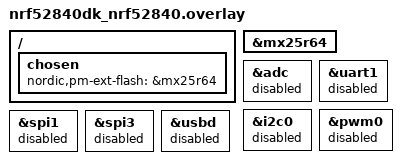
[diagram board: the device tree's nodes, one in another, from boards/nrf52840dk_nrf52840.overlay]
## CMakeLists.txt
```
#
# Nuki-to-Matter-over-Thread gateway.
# Based on the nRF Connect SDK Matter Bridge application
# (Copyright (c) 2023 Nordic Semiconductor ASA, LicenseRef-Nordic-5-Clause).
#

cmake_minimum_required(VERSION 3.20.0)

find_package(Zephyr HINTS $ENV{ZEPHYR_BASE})

project(nuki-matter-gateway)

# Bridge core, Matter identity, network log: firmware/common
include(${CMAKE_CURRENT_SOURCE_DIR}/../common/common.cmake)

target_include_directories(app PRIVATE
  src
  src/matter
  src/nuki
)

target_sources(app PRIVATE
  src/app_task.cpp
  src/main.cpp
  src/gateway_shell.cpp
  src/matter/door_lock_device.cpp
  src/matter/nuki_matter.cpp
  src/nuki/nuki_proto.c
  src/nuki/nuki_port.c
  src/nuki/nuki_client.cpp
  src/nuki/tweetnacl/tweetnacl.c
)
target_sources_ifdef(CONFIG_SHELL app PRIVATE src/nuki/nuki_shell.cpp)

# Status page (firmware/common/web): src/web/index.html and its JSON
target_sources_ifdef(CONFIG_GATEWAY_WEB app PRIVATE src/web_status.cpp)

# TweetNaCl as published (public domain, tweetnacl.cr.yp.to 20140427): no warnings for code we don't change
set_source_files_properties(src/nuki/tweetnacl/tweetnacl.c PROPERTIES COMPILE_OPTIONS "-w")

ncs_configure_data_model()
```

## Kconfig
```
#
# Nuki-to-Matter-over-Thread gateway.
# Based on the nRF Connect SDK Matter Bridge application
# (Copyright (c) 2023 Nordic Semiconductor, LicenseRef-Nordic-5-Clause).
#
mainmenu "Nuki-to-Matter-over-Thread Gateway"

# Bluetooth LE central for the lock, next to Matter's commissioning peripheral
config BT_CENTRAL
	default y

config BT_GATT_CLIENT
	default y

config BT_GATT_DM
	default y

# The Nuki thread waits on k_event bits set by the Bluetooth callbacks.
config EVENTS
	default y

menu "Nuki gateway"

config GATEWAY_NUKI_NAME
	string "Name of the gateway in the Nuki app"
	default "Thread Gateway"
	help
	  Sent to the lock when pairing; at most 32 bytes.

config GATEWAY_NUKI_APP_ID
	int "ID the gateway presents to the lock"
	default 2020003
	help
	  Sent when pairing and with every lock action (the lock's activity
	  log). The ESP32 bridge (nuki_matter) uses 2020002.

choice GATEWAY_NUKI_ID_TYPE
	prompt "Authorization type"
	default GATEWAY_NUKI_ID_TYPE_APP

config GATEWAY_NUKI_ID_TYPE_APP
	bool "App"
	help
	  The gateway pairs like a phone with the Nuki app. A lock accepts
	  several app authorizations, so this works next to a bridge (nuki_hub,
	  the ESP32 bridge or the Nuki Bridge).

config GATEWAY_NUKI_ID_TYPE_BRIDGE
	bool "Bridge"
	help
	  The gateway pairs as a bridge, like the Nuki Bridge, nuki_hub and the
	  ESP32 bridge.

endchoice

config GATEWAY_NUKI_LOCK_LABEL
	string "Matter name of the lock (endpoint 4)"
	default "Front door"
	help
	  Lock and Unlock move the bolt only.

config GATEWAY_NUKI_OPENER_LABEL
	string "Matter name of the door opener (endpoint 3)"
	default "Door opener"
	help
	  Unlock pulls the latch (opens the door); it then shows Locked again.

config GATEWAY_NUKI_POLL_INTERVAL_S
	int "Read the lock state at least this often (s)"
	default 600
	help
	  The lock's beacon flags new state, which is then read at once; the poll
	  only covers missed beacons.

config GATEWAY_NUKI_PAIRING_SEARCH_S
	int "Look for a lock in pairing mode this long after `nuki pair` (s)"
	default 60

config GATEWAY_NUKI_ACTION_ATTEMPTS
	int "Attempts per lock action"
	default 3
	help
	  A failed connection, a missing reply or a busy lock is retried.

config GATEWAY_NUKI_SCAN_INTERVAL
	int "Beacon scan interval (x0.625 ms)"
	default 160
	help
	  Passive scan for the lock's beacon while idle. Default: 160 (100 ms).

config GATEWAY_NUKI_SCAN_WINDOW
	int "Beacon scan window (x0.625 ms)"
	default 40
	help
	  Listening time per interval. Keep it well below the interval so Thread
	  keeps enough radio time. Default: 40 (25 ms, 25 % duty cycle).

config GATEWAY_NUKI_STACK_SIZE
	int "Stack size of the Nuki thread"
	default 5120
	help
	  TweetNaCl's Curve25519 (pairing only) needs about 2 KB.

module = GATEWAY_NUKI
module-str = Gateway Nuki
source "subsys/logging/Kconfig.template.log_config"

endmenu

rsource "../common/Kconfig"
```

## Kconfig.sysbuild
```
#
# Nuki-to-Matter-over-Thread gateway (nRF52840, single core).
# Based on the nRF Connect SDK Matter Bridge application
# (Copyright (c) 2023 Nordic Semiconductor, LicenseRef-Nordic-5-Clause).
#

# The Pro Micro has no external flash, so there is no room for a second image slot:
# it runs without MCUboot and the app uses the whole internal flash.
choice BOOTLOADER
	default BOOTLOADER_NONE if "$(BOARD)" = "promicro_nrf52840"
	default BOOTLOADER_MCUBOOT
endchoice

# Matter OTA needs MCUboot and the second slot.
config MATTER_OTA
	default n if "$(BOARD)" = "promicro_nrf52840"

if BOOTLOADER_MCUBOOT

config DFU_MULTI_IMAGE_PACKAGE_BUILD
	default y

config DFU_MULTI_IMAGE_PACKAGE_APP
	default y

endif # BOOTLOADER_MCUBOOT

config MATTER_FACTORY_DATA_GENERATE
	default y

source "share/sysbuild/Kconfig"
```

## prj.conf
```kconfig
#
# Copyright (c) 2023 Nordic Semiconductor ASA
#
# SPDX-License-Identifier: LicenseRef-Nordic-5-Clause
#

# This sample uses Kconfig.defaults to set options common for all
# samples. This file should contain only options specific for this sample
# or overrides of default values.

# Enable CHIP
CONFIG_CHIP=y
CONFIG_CHIP_PROJECT_CONFIG="src/chip_project_config.h"
CONFIG_CHIP_DEVICE_PRODUCT_NAME="Nuki Gateway"

# Configure ZAP file name
CONFIG_NCS_SAMPLE_MATTER_ZAP_FILE_PATH="${APPLICATION_CONFIG_DIR}/src/default_zap/bridge.zap"

# 32772 == 0x8004 (test product ID; the BLE gateway uses 0x8002, the EnOcean gateway 0x8003)
CONFIG_CHIP_DEVICE_PRODUCT_ID=32772
CONFIG_STD_CPP17=y

# Enable Matter pairing automatically on application start.
CONFIG_CHIP_ENABLE_PAIRING_AUTOSTART=y

# Enable Matter extended announcement and increase duration to 1 hour.
CONFIG_CHIP_BLE_EXT_ADVERTISING=y
CONFIG_CHIP_BLE_ADVERTISING_DURATION=60

# Add support for LEDs and buttons on Nordic development kits
CONFIG_DK_LIBRARY=y

# Bluetooth Low Energy configuration
CONFIG_BT_DEVICE_NAME="NukiGateway"

# Other settings
CONFIG_THREAD_NAME=y
CONFIG_MPU_STACK_GUARD=y
CONFIG_RESET_ON_FATAL_ERROR=n
CONFIG_CHIP_LIB_SHELL=y
CONFIG_NCS_SAMPLE_MATTER_TEST_SHELL=y

# Reduce assert verbosity to save flash space.
CONFIG_ASSERT_NO_FILE_INFO=y

# Disable NFC onboarding
CONFIG_CHIP_NFC_ONBOARDING_PAYLOAD=n

# Reduce application size
CONFIG_USE_SEGGER_RTT=n

# Enable Factory Data feature
CONFIG_CHIP_FACTORY_DATA=y
CONFIG_CHIP_FACTORY_DATA_BUILD=y

# Increase heap size to accommodate the memory required for additional bridged devices.
CONFIG_CHIP_MALLOC_SYS_HEAP_SIZE=16384

# Enable Shell
CONFIG_SHELL=y

# Peak use was 864 of the default 1152 B (wiki: Measurements)
CONFIG_SYSTEM_WORKQUEUE_STACK_SIZE=1536

# Nuki: log every request and state
CONFIG_GATEWAY_NUKI_LOG_LEVEL_INF=y

# Status page over HTTP (firmware/common/web). It needs TCP, which only OpenThread built
# from source has (the prebuilt Nordic library is built without it).
CONFIG_OPENTHREAD_SOURCES=y
CONFIG_GATEWAY_WEB=y
```

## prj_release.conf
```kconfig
#
# Copyright (c) 2023 Nordic Semiconductor ASA
#
# SPDX-License-Identifier: LicenseRef-Nordic-5-Clause
#

# This sample uses Kconfig.defaults to set options common for all
# samples. This file should contain only options specific for this sample
# or overrides of default values.

# Enable CHIP
CONFIG_CHIP=y
CONFIG_CHIP_PROJECT_CONFIG="src/chip_project_config.h"
CONFIG_CHIP_DEVICE_PRODUCT_NAME="Nuki Gateway"

# Configure ZAP file name
CONFIG_NCS_SAMPLE_MATTER_ZAP_FILE_PATH="${APPLICATION_CONFIG_DIR}/src/default_zap/bridge.zap"

# 32772 == 0x8004 (test product ID; the BLE gateway uses 0x8002, the EnOcean gateway 0x8003)
CONFIG_CHIP_DEVICE_PRODUCT_ID=32772
CONFIG_STD_CPP17=y

# Enable Matter pairing automatically on application start.
CONFIG_CHIP_ENABLE_PAIRING_AUTOSTART=y

# Enable Matter extended announcement and increase duration to 1 hour.
CONFIG_CHIP_BLE_EXT_ADVERTISING=y
CONFIG_CHIP_BLE_ADVERTISING_DURATION=60

# Add support for LEDs and buttons on Nordic development kits
CONFIG_DK_LIBRARY=y

# Bluetooth Low Energy configuration
CONFIG_BT_DEVICE_NAME="NukiGateway"

# Enable system reset on fatal error
CONFIG_RESET_ON_FATAL_ERROR=y

# Disable all debug features
CONFIG_USE_SEGGER_RTT=n
CONFIG_OPENTHREAD_SHELL=n
CONFIG_LOG=n
CONFIG_LOG_MODE_MINIMAL=n
CONFIG_ASSERT_VERBOSE=n
CONFIG_ASSERT_NO_FILE_INFO=y
CONFIG_PRINTK=n
CONFIG_PRINTK_SYNC=n
CONFIG_THREAD_NAME=n
CONFIG_BOOT_BANNER=n

# Disable NFC onboarding
CONFIG_CHIP_NFC_ONBOARDING_PAYLOAD=n

# Enable Factory Data feature
CONFIG_CHIP_FACTORY_DATA=y
CONFIG_CHIP_FACTORY_DATA_BUILD=y

# Enable the Read Client for binding purposes
CONFIG_CHIP_ENABLE_READ_CLIENT=y

# Enable Watchdog
CONFIG_NCS_SAMPLE_MATTER_WATCHDOG=y

# Enable LTO to decrease the flash usage.
CONFIG_LTO=y
CONFIG_ISR_TABLES_LOCAL_DECLARATION=y

# Increase heap size to accommodate the memory required for additional bridged devices.
CONFIG_CHIP_MALLOC_SYS_HEAP_SIZE=16384

# Enable Shell
CONFIG_SHELL=y

# Peak use was 864 of the default 1152 B (wiki: Measurements)
CONFIG_SYSTEM_WORKQUEUE_STACK_SIZE=1536

# Status page over HTTP (firmware/common/web). It needs TCP, which only OpenThread built
# from source has (the prebuilt Nordic library is built without it).
CONFIG_OPENTHREAD_SOURCES=y
CONFIG_GATEWAY_WEB=y
```

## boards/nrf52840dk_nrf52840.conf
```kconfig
# Matter's commissioning peripheral + the connection to the lock
CONFIG_BT_MAX_CONN=2
# The lock as two bridged endpoints (front door, door opener), plus room
CONFIG_BRIDGE_MAX_BRIDGED_DEVICES_NUMBER=4
CONFIG_BRIDGE_MAX_DYNAMIC_ENDPOINTS_NUMBER=4
CONFIG_BRIDGE_MAX_BRIDGED_DEVICES_NUMBER_PER_PROVIDER=1
CONFIG_LTO=y
CONFIG_ISR_TABLES_LOCAL_DECLARATION=y
```

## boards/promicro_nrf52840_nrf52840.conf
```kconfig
# Pro Micro nRF52840, flashed over SWD. Same limits as the DK (boards/nrf52840dk_nrf52840.conf).
# Matter's commissioning peripheral + the connection to the lock
CONFIG_BT_MAX_CONN=2
# The lock as two bridged endpoints (front door, door opener), plus room
CONFIG_BRIDGE_MAX_BRIDGED_DEVICES_NUMBER=4
CONFIG_BRIDGE_MAX_DYNAMIC_ENDPOINTS_NUMBER=4
CONFIG_BRIDGE_MAX_BRIDGED_DEVICES_NUMBER_PER_PROVIDER=1
CONFIG_LTO=y
CONFIG_ISR_TABLES_LOCAL_DECLARATION=y

# Flashed over SWD with the UF2 bootloader erased: link at 0x0, not after the MBR.
CONFIG_BOARD_HAS_NRF5_BOOTLOADER=n
CONFIG_USE_DT_CODE_PARTITION=y

# Many clones have no 32.768 kHz crystal; the RC oscillator works on all of them.
CONFIG_CLOCK_CONTROL_NRF_K32SRC_RC=y
CONFIG_CLOCK_CONTROL_NRF_K32SRC_500PPM=y

# Console and shell run over USB (CDC ACM); the board sets that up itself.

# No MCUboot, so no Matter DFU (see Kconfig.sysbuild).
CONFIG_CHIP_BOOTLOADER_NONE=y
```

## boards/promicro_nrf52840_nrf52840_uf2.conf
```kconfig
# Pro Micro nRF52840 with the UF2 bootloader kept. Same as
# promicro_nrf52840_nrf52840.conf, except the linking: the board's uf2 variant
# links into the DT code partition (0x1000, after the MBR).
# Matter's commissioning peripheral + the connection to the lock
CONFIG_BT_MAX_CONN=2
# The lock as two bridged endpoints (front door, door opener), plus room
CONFIG_BRIDGE_MAX_BRIDGED_DEVICES_NUMBER=4
CONFIG_BRIDGE_MAX_DYNAMIC_ENDPOINTS_NUMBER=4
CONFIG_BRIDGE_MAX_BRIDGED_DEVICES_NUMBER_PER_PROVIDER=1
CONFIG_LTO=y
CONFIG_ISR_TABLES_LOCAL_DECLARATION=y

# Many clones have no 32.768 kHz crystal; the RC oscillator works on all of them.
CONFIG_CLOCK_CONTROL_NRF_K32SRC_RC=y
CONFIG_CLOCK_CONTROL_NRF_K32SRC_500PPM=y

# Console and shell run over USB (CDC ACM); the board sets that up itself.

# No MCUboot, so no Matter DFU (see Kconfig.sysbuild).
CONFIG_CHIP_BOOTLOADER_NONE=y

# Zephyr's own zephyr.uf2 can't find the load address with this partition layout,
# and it would lack the factory data. scripts/make-uf2.py builds gateway.uf2 instead.
CONFIG_BUILD_OUTPUT_UF2=n
```

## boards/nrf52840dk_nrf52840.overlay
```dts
/*
 * Copyright (c) 2021 Nordic Semiconductor ASA
 *
 * SPDX-License-Identifier: LicenseRef-Nordic-5-Clause
 */

#include <samples/matter/nrf52840_partitions.dtsi>
#include "../../common/boards/nrf52840dk_status_leds.dtsi"

/ {
	chosen {
		nordic,pm-ext-flash = &mx25r64;
	};
};

&mx25r64 {
	status = "okay";
};

/* Disable unused peripherals to reduce power consumption */
&adc {
	status = "disabled";
};

&uart1 {
	status = "disabled";
};

&i2c0 {
	status = "disabled";
};

&pwm0 {
	status = "disabled";
};

&spi1 {
	status = "disabled";
};

&spi3 {
	status = "disabled";
};

&usbd {
	status = "disabled";
};
```

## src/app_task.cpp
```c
/*
 * Nuki-to-Matter-over-Thread gateway.
 * Based on the nRF Connect SDK Matter Bridge application
 * (Copyright (c) 2023 Nordic Semiconductor ASA, LicenseRef-Nordic-5-Clause).
 *
 * The lock appears as two bridged Door Lock endpoints (src/matter/nuki_matter.h) and in the shell (`nuki ...`).
 */

#include "app_task.h"
#include "nuki_client.h"
#include "nuki_matter.h"
#ifdef CONFIG_GATEWAY_IDENTITY_FROM_CHIP_ID
#include "identity/chip_id_identity.h"
#endif
#ifdef CONFIG_GATEWAY_NET_LOG
#include "netlog/net_log.h"
#endif
#ifdef CONFIG_GATEWAY_STATUS_LEDS
#include "status_leds/status_leds.h"
#endif
#ifdef CONFIG_GATEWAY_WEB
#include "web/web_server.h"
#include "web_status.h"
#endif

#include "ota/gateway_ota.h"
#include "app/matter_init.h"
#include "app/task_executor.h"
#include "board/board.h"
#include "bridge_manager.h"
#include "bridge_storage_manager.h"
#include "clusters/identify.h"

#include <zephyr/logging/log.h>

LOG_MODULE_DECLARE(app, CONFIG_CHIP_APP_LOG_LEVEL);

using namespace ::chip;
using namespace ::chip::app;
using namespace ::chip::DeviceLayer;

namespace
{

constexpr EndpointId kBridgeEndpointId = 1;

/* Trigger effect is enabled for the bridge device */
Nrf::Matter::IdentifyCluster sIdentifyCluster(kBridgeEndpointId, true);

#ifndef CONFIG_CHIP_FACTORY_RESET_ERASE_SETTINGS
void AppFactoryResetHandler(const ChipDeviceEvent *event, intptr_t /* unused */)
{
	switch (event->Type) {
	case DeviceEventType::kFactoryReset:
		Nrf::BridgeStorageManager::Instance().FactoryReset();
		break;
	default:
		break;
	}
}
#endif

#ifdef CONFIG_GATEWAY_IDENTITY_FROM_CHIP_ID
Gateway::ChipIdFactoryDataProvider sChipIdFactoryDataProvider;
#endif

#ifdef CONFIG_GATEWAY_STATUS_LEDS
/* The lock beacons every few seconds; this long without one means it's out of reach. */
constexpr int64_t kBeaconLostMs = 60 * 1000;

/*
 * PWR (red):  on               paired, the lock is heard and the last request went through
 *             fast blink       looking for a lock in pairing mode (`nuki pair`)
 *             slow even blink  paired, but the lock isn't reached (no beacon for 60 s,
 *                              or the last request failed to connect)
 *             short flash      not paired
 * RX (yellow) is on while a connection to the lock is open (nuki_matter.cpp).
 */
Gateway::StatusLeds::Pwr PwrPattern()
{
	using Gateway::StatusLeds::Pwr;
	using Gateway::Nuki::Result;
	Gateway::Nuki::Snapshot s;

	Gateway::Nuki::GetSnapshot(s);
	if (s.mSearching) {
		return Pwr::Activity;
	}
	if (!s.mPaired) {
		return Pwr::Fault;
	}
	const bool beaconLost = s.mLastBeaconMs == 0 || k_uptime_get() - s.mLastBeaconMs > kBeaconLostMs;
	const bool unreachable = s.mLastResult == Result::ConnectFailed || s.mLastResult == Result::Timeout ||
				 s.mLastResult == Result::Disconnected;

	return beaconLost || unreachable ? Pwr::Warning : Pwr::On;
}
#endif

} /* namespace */

CHIP_ERROR AppTask::RestoreBridgedDevices()
{
	/* The door lock endpoints are fixed and added by NukiMatter::Init, not stored. */
	return CHIP_NO_ERROR;
}

CHIP_ERROR AppTask::Init()
{
	/* Initialize Matter stack */
	ReturnErrorOnFailure(Nrf::Matter::PrepareServer(Nrf::Matter::InitData{
#ifdef CONFIG_GATEWAY_IDENTITY_FROM_CHIP_ID
		.mFactoryDataProvider = &sChipIdFactoryDataProvider,
#endif
		.mPostServerInitClbk = [] {
		CHIP_ERROR err = Nrf::BridgeManager::Instance().Init(RestoreBridgedDevices);
		if (err != CHIP_NO_ERROR) {
			LOG_ERR("BridgeManager initialization failed");
			return err;
		}

		/* Door lock endpoints and the Nuki client; Bluetooth is up now (Matter's commissioning peripheral). */
		/* Not fatal: Matter keeps running (and can be reached for a fix). */
		err = Gateway::NukiMatter::Init();
		if (err != CHIP_NO_ERROR) {
			LOG_ERR("Nuki endpoints initialization failed: %" CHIP_ERROR_FORMAT, err.Format());
		}
#ifdef CONFIG_GATEWAY_NET_LOG
		Gateway::NetLog::Init();
#endif
#ifdef CONFIG_GATEWAY_WEB
		Gateway::Web::Init(Gateway::WriteWebStatus);
#endif
		return CHIP_NO_ERROR;
	} }));

	if (!Nrf::GetBoard().Init()) {
		LOG_ERR("User interface initialization failed.");
		return CHIP_ERROR_INCORRECT_STATE;
	}
#ifdef CONFIG_GATEWAY_STATUS_LEDS
	Gateway::StatusLeds::InitPattern(PwrPattern);
#endif

	/* Register Matter event handler that controls the connectivity status LED based on the captured Matter
	 * network state. */
	ReturnErrorOnFailure(Nrf::Matter::RegisterEventHandler(Nrf::Board::DefaultMatterEventHandler, 0));

#ifndef CONFIG_CHIP_FACTORY_RESET_ERASE_SETTINGS
	/* The whole settings partition is not erased on factory reset; clean up the bridge storage. */
	ReturnErrorOnFailure(Nrf::Matter::RegisterEventHandler(AppFactoryResetHandler, 0));
#endif

	ReturnErrorOnFailure(sIdentifyCluster.Init());

#ifdef CONFIG_GATEWAY_OTA
	ReturnErrorOnFailure(Gateway::Ota::Init());
#endif

	return Nrf::Matter::StartServer();
}

CHIP_ERROR AppTask::StartApp()
{
	ReturnErrorOnFailure(Init());

	while (true) {
		Nrf::DispatchNextTask();
	}

	return CHIP_NO_ERROR;
}
```

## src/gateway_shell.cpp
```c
/*
 * `gateway ...` shell commands of the Nuki gateway (shared with the BLE and EnOcean gateways,
 * firmware/common/identity/identity_shell.h):
 *   gateway identity     chip ID, serial number and Matter setup code
 *   gateway bootloader   restart into the UF2 bootloader (Pro Micro UF2 builds)
 */

#include "identity/identity_shell.h"

#include <zephyr/shell/shell.h>

SHELL_STATIC_SUBCMD_SET_CREATE(
	sub_gateway,
	SHELL_CMD_ARG(identity, NULL, "Show chip ID, serial number and the Matter setup code.",
		      Gateway::IdentityShell::CmdIdentity, 1, 0),
	SHELL_COND_CMD_ARG(IS_ENABLED(CONFIG_GATEWAY_UF2_BOOTLOADER_CMD), bootloader, NULL,
			   "Restart into the UF2 bootloader, which then shows up as a USB drive.",
			   COND_CODE_1(CONFIG_GATEWAY_UF2_BOOTLOADER_CMD, (Gateway::IdentityShell::CmdBootloader),
				       (NULL)),
			   1, 0),
	SHELL_SUBCMD_SET_END);

SHELL_CMD_REGISTER(gateway, &sub_gateway, "Gateway identity", NULL);
```

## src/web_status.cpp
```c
/*
 * Status JSON of the Nuki gateway for the web page (src/web/index.html). See web_status.h.
 */

#include "web_status.h"

#include "bridge_manager.h"
#include "door_lock_device.h"
#include "nuki_client.h"
#include "nuki_matter.h"
#include "web/status_json.h"

#include <zephyr/bluetooth/addr.h>
#include <zephyr/kernel.h>

#include <stdio.h>

using Gateway::Web::Json;
namespace Nuki = Gateway::Nuki;

namespace
{

/* Matter thread: the endpoints are only touched there. */
void WriteEndpoint(Json &j, chip::EndpointId endpoint)
{
	uint8_t index;
	auto *device = static_cast<DoorLockDevice *>(Nrf::BridgeManager::Instance().GetDevice(endpoint, index));

	if (!device) {
		return;
	}
	j.Open(nullptr, '{');
	j.Int("endpoint", endpoint);
	j.Str("name", device->GetNodeLabel());
	j.Str("role", device->GetRole() == DoorLockDevice::Role::Lock ? "lock" : "opener");
	j.Bool("reachable", device->GetIsReachable());
	switch (device->GetLockState()) {
	case 0: j.Str("state", "not fully locked"); break;
	case 1: j.Str("state", "locked"); break;
	case 2: j.Str("state", "unlocked"); break;
	case 3: j.Str("state", "unlatched"); break;
	default: j.Null("state"); break;
	}
	j.Close('}');
}

void WriteNuki(Json &j)
{
	Nuki::Snapshot s;
	const int64_t now = k_uptime_get();
	char text[BT_ADDR_LE_STR_LEN];

	Nuki::GetSnapshot(s);
	j.Open("nuki", '{');
	j.Bool("paired", s.mPaired);
	j.Bool("searching", s.mSearching);
	j.Bool("busy", s.mBusy);
	if (s.mPaired) {
		bt_addr_le_to_str(&s.mAddr, text, sizeof(text));
		j.Str("address", text, 17);
		j.Int("authId", s.mAuthId);
	}
	if (s.mLastBeaconMs) {
		j.Int("rssi", s.mRssi);
		j.Int("beaconAgoS", (now - s.mLastBeaconMs) / 1000);
	} else {
		j.Null("rssi");
		j.Null("beaconAgoS");
	}

	if (s.mHaveState) {
		j.Open("lock", '{');
		j.Str("state", nuki_lock_state_str(s.mState.lock_state));
		j.Int("code", s.mState.lock_state);
		j.Str("door", nuki_door_state_str(s.mState.door_state));
		j.Bool("doorSensor", s.mState.door_state != NUKI_DOOR_UNAVAILABLE && s.mState.door_state != NUKI_DOOR_NONE);
		j.Int("battery", nuki_battery_percent(s.mState.battery_raw));
		j.Bool("critical", nuki_battery_critical(s.mState.battery_raw));
		j.Bool("charging", nuki_battery_charging(s.mState.battery_raw));
		j.Int("agoS", (now - s.mStateMs) / 1000);
		j.Close('}');
	} else {
		j.Null("lock");
	}

	if (s.mHaveInfo) {
		j.Open("info", '{');
		j.Str("name", s.mInfo.name);
		snprintf(text, sizeof(text), "%08X", unsigned(s.mInfo.nuki_id));
		j.Str("nukiId", text);
		snprintf(text, sizeof(text), "%u.%u.%u", s.mInfo.firmware[0], s.mInfo.firmware[1], s.mInfo.firmware[2]);
		j.Str("firmware", text);
		snprintf(text, sizeof(text), "%u.%u", s.mInfo.hardware[0], s.mInfo.hardware[1]);
		j.Str("hardware", text);
		j.Close('}');
	} else {
		j.Null("info");
	}

	j.Int("requests", s.mRequests);
	j.Int("failures", s.mFailures);
	j.Str("lastResult", Nuki::ResultStr(s.mLastResult));
	if (s.mLastResult == Nuki::Result::LockError) {
		j.Str("lastError", nuki_error_str(s.mLastError));
	} else {
		j.Null("lastError");
	}
	j.Int("connects", s.mConnects);
	j.Int("connectFailures", s.mConnectFailures);
	if (s.mConnects) {
		snprintf(text, sizeof(text), "0x%02X", s.mLastDisconnectReason);
		j.Str("lastDisconnect", text);
	} else {
		j.Null("lastDisconnect");
	}
	j.Bool("scanning", s.mScanning);
	j.Int("advertisements", s.mAdvertisements);
	j.Int("scanError", s.mScanError);
	j.Str("name", CONFIG_GATEWAY_NUKI_NAME);
	j.Close('}');
}

} /* namespace */

namespace Gateway
{

size_t WriteWebStatus(char *buf, size_t size)
{
	Json j(buf, size);

	j.Open(nullptr, '{');
	Gateway::Web::WriteCommonStatus(j);
	WriteNuki(j);
	/* Front door first, then the opener */
	j.Open("endpoints", '[');
	WriteEndpoint(j, Gateway::NukiMatter::kLockEndpointId);
	WriteEndpoint(j, Gateway::NukiMatter::kOpenerEndpointId);
	j.Close(']');
	j.Close('}');
	return j.Done();
}

} /* namespace Gateway */
```

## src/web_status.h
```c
/*
 * Status JSON of the Nuki gateway for the web page (src/web/index.html):
 * system, Thread, Matter, the lock (Bluetooth link, state, battery) and the two Matter endpoints.
 */

#pragma once

#include <stddef.h>

namespace Gateway
{

/* A Gateway::Web::StatusWriter: Matter thread, returns 0 if the JSON does not fit. */
size_t WriteWebStatus(char *buf, size_t size);

} /* namespace Gateway */
```
